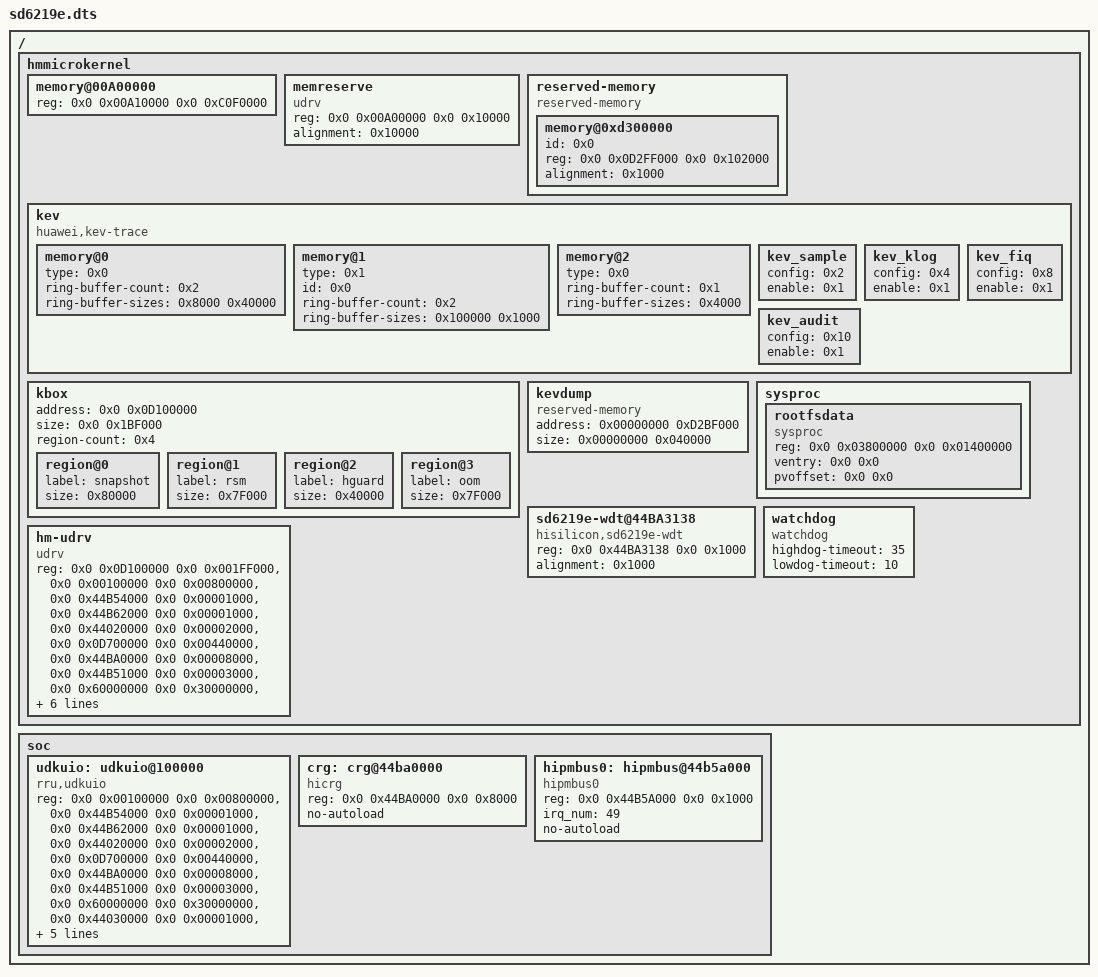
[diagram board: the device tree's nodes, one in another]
/*
 * Device Tree Include file for WUYI SD6219e Board
 */

/dts-v1/;
/memreserve/ 0x00A00000 0x00010000;

/include/ "sd6219e.dtsi"

/ {
	hmmicrokernel {
		memory@00A00000 {
			device_type = "memory";
			/* 0xA00000 - 0xA0FFFF is reserved */
			reg = <0x0 0x00A10000 0x0 0xC0F0000>; /* could only use 192M here */
			      /* <0x0 0x13000000 0x0 0x8000000>;*/ /* 128M for SRE */
		};

		/* we don't support /memreserve/, using a node to reserve memory */
		memreserve {
			#address-cells = <2>;
			#size-cells = <2>;
			compatible = "udrv", "memreserve";

			reg = <0x0 0x00A00000 0x0 0x10000>;
			alignment = <0x10000>;
		};

		reserved-memory {
			compatible = "reserved-memory";
			#address-cells = <2>;
			#size-cells = <2>;
			memory@0xd300000 {
				id = <0x0>;
				reg = <0x0 0x0D2FF000 0x0 0x102000>;
				alignment = <0x1000>;
			};
		};

		kev {
			compatible = "huawei,kev-trace";

			memory@0 {
				type = <0x0>;
				ring-buffer-count = <0x2>;
				/*
				 * ring buffer 0: 32K
				 * ring buffer 1: 256K
				 */
				ring-buffer-sizes = <0x8000 0x40000>;
			};

			memory@1 {
				type = <0x1>; /* reserved memory */
				id = <0x0>;
				ring-buffer-count = <0x2>;
				/*
				 * Only ring buffer DATA sizes. Memory head and ring
				 * buffer heads are not included.
				 * ring buffer 2: 1MB(klog)
				 * ring buffer 3: 4K(fiq)
				 */
				ring-buffer-sizes = <0x100000 0x1000>;
			};

			memory@2 {
				type = <0x0>;
				ring-buffer-count = <0x1>;
				/*
				 * ring buffer 4: 16K(audit)
				 */
				ring-buffer-sizes = <0x4000>;
			};
			kev_sample {
				config = <0x2>;
				enable = <0x1>;
			};
			kev_klog {
				config = <0x4>;
				enable = <0x1>;
			};
			kev_fiq {
				config = <0x8>;
				enable = <0x1>;
			};
			kev_audit {
				config = <0x10>;
				enable = <0x1>;
			};
		};

		kbox {
			address = <0x0 0x0D100000>;
			size = <0x0 0x1BF000>;
			region-count= <0x4>;
			region@0 {
				label = "snapshot";
				size = <0x80000>;
			};
			region@1 {
				label = "rsm";
				size = <0x7F000>;
			};
			region@2 {
				label = "hguard";
				size = <0x40000>;
			};
			region@3 {
				label = "oom";
				size = <0x7F000>;
			};
		};

		kevdump {
			compatible = "reserved-memory";
			address = <0x00000000 0xD2BF000>;
			size = <0x00000000 0x040000>;
		};

		sysproc {
			/* Describe board boot param rootfs in top level dts */
			rootfsdata {
				compatible = "sysproc", "rootfs";
				reg = <0x0 0x03800000 0x0 0x01400000>;
				ventry = <0x0 0x0>;
				/* filled by bootloader */
				pvoffset = <0x0 0x0>;
			};
		};

		/* SD6219E CPU use a dedicated watchdog */
		sd6219e-wdt@44BA3138 {
			compatible = "hisilicon,sd6219e-wdt";
			#address-cells = <2>;
			#size-cells = <2>;

			reg = <0x0 0x44BA3138 0x0 0x1000>;
			alignment = <0x1000>;
		};

		watchdog {
			compatible = "watchdog";
			/* reserve 35s for hguard to take over the watchdog */
			highdog-timeout = <35>;
			/* reserve 10s for subcore to be pulled up*/
			lowdog-timeout = <10>;
		};

		hm-udrv {
			compatible = "udrv";
			reg =
			      <0x0 0x0D100000 0x0 0x001FF000>, /* kbox */
			      <0x0 0x00100000 0x0 0x00800000>, /* BSPLOG */
			      <0x0 0x44B54000 0x0 0x00001000>, /* uart */
			      <0x0 0x44B62000 0x0 0x00001000>, /* comm */
			      <0x0 0x44020000 0x0 0x00002000>, /* femac */
			      <0x0 0x0D700000 0x0 0x00440000>, /* pramdisk */
			      <0x0 0x44BA0000 0x0 0x00008000>, /* crg */
			      <0x0 0x44B51000 0x0 0x00003000>, /* espi */
			      <0x0 0x60000000 0x0 0x30000000>, /* espi */
			      <0x0 0x44030000 0x0 0x00001000>, /* spi */
			      <0x0 0x44B5D000 0x0 0x00005000>, /* gpio_set */
			      <0x0 0x44B88000 0x0 0x00005000>, /* gpio_set */
			      <0x0 0x44B98000 0x0 0x00004000>, /* gpio */
			      <0x0 0x44B5A000 0x0 0x00001000>, /* pmbus0 */
			      <0x0 0x44B62000 0x0 0x00001000>; /* sysctrl */
		};
	};

	soc {
		udkuio: udkuio@100000 {
			compatible = "rru,udkuio", "udkuio";
			reg = <0x0 0x00100000 0x0 0x00800000>, /* BSPLOG */
			      <0x0 0x44B54000 0x0 0x00001000>, /* uart */
			      <0x0 0x44B62000 0x0 0x00001000>, /* comm */
			      <0x0 0x44020000 0x0 0x00002000>, /* femac */
			      <0x0 0x0D700000 0x0 0x00440000>, /* pramdisk */
			      <0x0 0x44BA0000 0x0 0x00008000>, /* crg */
			      <0x0 0x44B51000 0x0 0x00003000>, /* espi */
			      <0x0 0x60000000 0x0 0x30000000>, /* espi */
			      <0x0 0x44030000 0x0 0x00001000>, /* spi */
			      <0x0 0x44B5D000 0x0 0x00005000>, /* gpio_set */
			      <0x0 0x44B88000 0x0 0x00005000>, /* gpio_set */
			      <0x0 0x44B98000 0x0 0x00004000>, /* gpio */
			      <0x0 0x44B5A000 0x0 0x00001000>, /* pmbus0 */
			      <0x0 0x44B62000 0x0 0x00001000>; /* sysctrl */
		};

		crg: crg@44ba0000 {
			compatible = "hicrg";
			reg = <0x0 0x44BA0000 0x0 0x8000>;
			no-autoload;
		};

		hipmbus0: hipmbus@44b5a000 {
			compatible = "hipmbus0";
			reg = <0x0 0x44B5A000 0x0 0x1000>;
			irq_num  = <49>;
			no-autoload;
		};
	};
};
